# STM32H5E5 register map
File version: 1.0
CPU: CM33 r0p0, little endian, MPU, FPU, 4 interrupt priority bits
Registers are 32-bit, read-write, reset 0x0 unless marked. A register's access mark holds for its fields unless they carry their own. Offsets are from the block's base; [hi:lo] are bit positions; {n}, {i} and the like mark numbered series; 'fields as' and 'values as' point back to an identical list.

## SBS — SBS address block description
Base 0x44000400
Same registers: SBS_S 0x54000400
0x10 SBS_HDPLCR reset 0xB4 — SBS temporal isolation control register
  [7:0] INCR_HDPL — Increment HDPL value
    180=No increment; 106=Recommended value to increment HDPL level by one
0x14 SBS_HDPLSR ro reset not defined — SBS temporal isolation status register
  [7:0] HDPL — Temporal isolation level
    180=HDPL0, RSS; 81=HDPL1, iRoT; 138=HDPL2, uRoT; 111=HDPL3, application (secure)
0x18 SBS_NEXTHDPLCR — SBS next HDPL control register
  [1:0] NEXTHDPL — Index to point to a higher HDPL than the current one
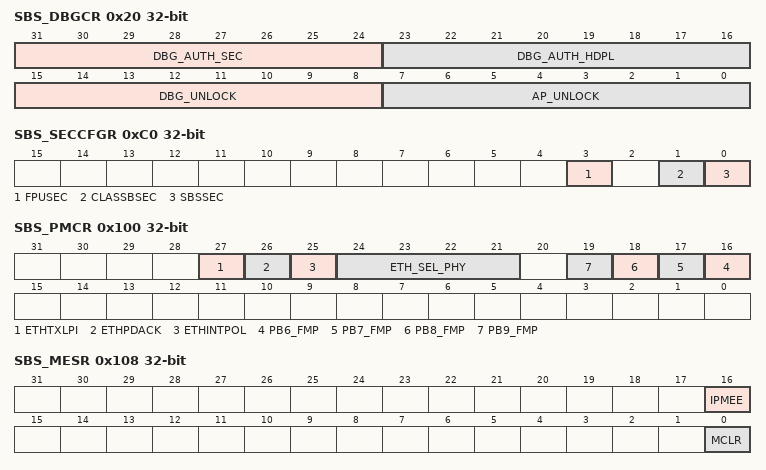
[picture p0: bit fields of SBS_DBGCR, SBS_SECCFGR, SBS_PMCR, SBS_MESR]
0x20 SBS_DBGCR — SBS debug control register
  [31:24] DBG_AUTH_SEC — Control debug opening secure/
  [23:16] DBG_AUTH_HDPL — Authenticated debug temporal isolation level
    81=HDPL1; 138=HDPL2; 111=HDPL3
  [15:8] DBG_UNLOCK — Debug unlock when DBG_AUTH_HDPL is reached
  [7:0] AP_UNLOCK — Access port unlock
0x24 SBS_DBGLOCKR reset 0xB4 — SBS debug lock register
  [7:0] DBGCFG_LOCK — Debug configuration lock
    180=Writes to SBS_DBGCR allowed (default)
0x34 SBS_RSSCMDR — SBS RSS command register
  [15:0] RSSCMD — RSS command
0xA0 SBS_EPOCHSELCR — SBS EPOCH selection control register
  [1:0] EPOCH_SEL — Select EPOCH value to be sent to the SAES
    0=NS_EPOCH () counter input selected; 1=SEC_EPOCH counter input selected
0xC0 SBS_SECCFGR — SBS security mode configuration control register
  [3] FPUSEC — FPU security enable
    0=SBS_FPUIMP register accessible through secure or transaction; 1=SBS_FPUIMP register accessible only through secure transaction
  [1] CLASSBSEC — ClassB security enable
    0=SBS_CFGR2 register accessible through secure or transaction; 1=SBS_CFGR2 register accessible only through secure transaction
  [0] SBSSEC — SBS clock control, memory-erase status register and compensation cell register security enable
    0=SBS_MESR, SBS_CCCSR, SBS_CCVALR, SBS_CCSWCR registers accessible through secure or transaction; 1=SBS_MESR, SBS_CCCSR, SBS_CCVALR, SBS_CCSWCR registers accessible only through secure transaction
0x100 SBS_PMCR — SBS product mode and configuration register
  [27] ETHTXLPI ro — ETH TxLPI status
  [26] ETHPDACK ro — ETH power-down acknowledge
    0=ETH functional / power-down sequence not yet completed; 1=ETH power-down sequence completed
  [25] ETHINTPOL — ETH external PHY interrupt polarity configuration
    0=active high; 1=active low
  [24:21] ETH_SEL_PHY — Ethernet PHY interface selection
    0=GMII or MII; 4=RMII; 8=10BT1S
  [n+10] PB{n}_FMP (n=6..9) — Fast-mode Plus driving capability activation on PB{n}
    0=PB{n} pin operates in standard mode; 1=Fm+ mode is enabled on PB{n} pin and the speed control is bypassed
0x104 SBS_FPUIMR reset 0x1F — SBS FPU interrupt mask register
  [5:0] FPU_IE — FPU interrupt enable
0x108 SBS_MESR (reset mask 0xFFFFFFF0) — SBS memory erase status register
  [16] IPMEE — ICACHE erase status
    0=ICACHE and PKA RAM erase ongoing; 1=ICACHE and PKA SRAM erase done
  [0] MCLR — device memories erase status
    0=memory erase ongoing if not yet cleared by software; 1=Memory erase done
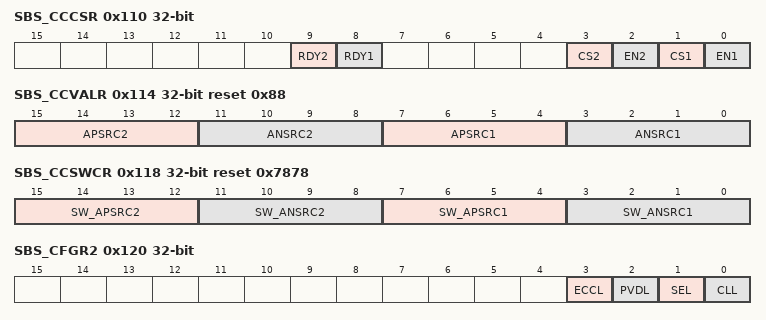
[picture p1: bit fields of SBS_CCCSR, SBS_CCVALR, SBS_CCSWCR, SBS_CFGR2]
0x110 SBS_CCCSR — SBS compensation cell for I/Os control and status register
  [9] RDY2 ro — VDDIO2 compensation cell ready flag
    0=VDDIO2 compensation cell not ready; 1=VDDIO2 compensation cell ready (code value provided by the cell can be used)
  [8] RDY1 ro — VDDIO compensation cell ready flag
    0=VDDIO compensation cell not ready; 1=VDDIO compensation cell ready (code value provided by the cell can be used)
  [3] CS2 — code selection for VDDIO2 power rail (reset value set to 1)
    0=Code from the cell (available in SBS_CCVR); 1=Code from SBS_CCCR
  [2] EN2 — enable compensation cell for VDDIO2 power rail
    0=I/O compensation cell disabled; 1=I/O compensation cell enabled
  [1] CS1 — code selection for VDDIO power rail (reset value set to 1)
    0=Code from the cell (available in the SBS_CCVR); 1=Code from SBS_CCCR
  [0] EN1 — enable compensation cell for VDDIO power rail
    values as EN2
0x114 SBS_CCVALR ro reset 0x88 — SBS compensation cell for I/Os value register
  [15:12] APSRC2 — compensation value for the PMOS transistor
  [11:8] ANSRC2 — Compensation value for the NMOS transistor
  [7:4] APSRC1 — compensation value for the PMOS transistor
  [3:0] ANSRC1 — compensation value for the NMOS transistor
0x118 SBS_CCSWCR reset 0x7878 — SBS compensation cell for I/Os software code register
  [15:12] SW_APSRC2 — PMOS compensation code for the Vless thansub>DDIOless than/sub> power rails
  [11:8] SW_ANSRC2 — NMOS compensation code for VDDIO power rails
  [7:4] SW_APSRC1 — PMOS compensation code for the VDD power rails
  [3:0] SW_ANSRC1 — NMOS compensation code for VDD power rails
0x120 SBS_CFGR2 — SBS Class B register
  [3] ECCL — ECC lock
    0=double ECC error flag disconnected to timer break inputs; 1=double ECC error flag connected to timer break inputs
  [2] PVDL — PVD lock
    0=PVD interrupt disconnected from timer break inputs; 1=PVD interrupt is connected to timer break inputs
  [1] SEL — SRAM ECC error lock
    0=SRAM double ECC error flag disconnected from timer break inputs; 1=SRAM double ECC error flag connected to timer break inputs
  [0] CLL — core lockup lock
    0=lockup output disconnected from timer break inputs; 1=lockup output connected to timer break inputs
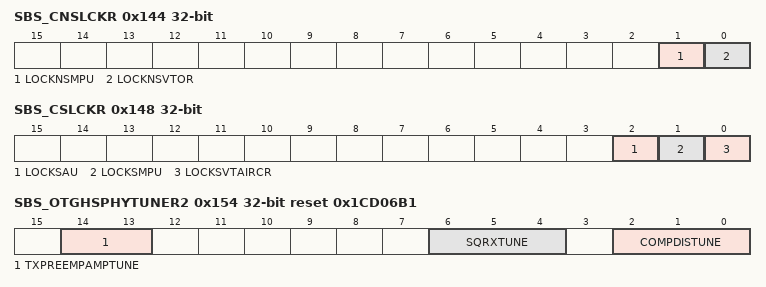
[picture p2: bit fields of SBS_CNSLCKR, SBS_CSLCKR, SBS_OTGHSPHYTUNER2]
0x144 SBS_CNSLCKR — SBS CPU lock register
  [1] LOCKNSMPU — MPU register lock
    0=MPU registers write enabled; 1=MPU registers write disabled
  [0] LOCKNSVTOR — VTOR_NS register lock
    0=VTOR_NS register write enabled; 1=VTOR_NS register write disabled
0x148 SBS_CSLCKR — SBS CPU secure lock register
  [2] LOCKSAU — SAU registers lock
    0=SAU registers write enabled; 1=SAU registers write disabled
  [1] LOCKSMPU — secure MPU registers lock
    0=Secure MPU registers writes enabled; 1=Secure MPU registers writes disabled
  [0] LOCKSVTAIRCR — VTOR_S and AIRCR register lock
    0=VTOR_S register PRIS and BFHFNMINS bits in the AIRCR register write enabled; 1=VTOR_S register PRIS and BFHFNMINS bits in the AIRCR register write disabled
0x14C SBS_ECCNMIR — SBS flift ECC NMI mask register
  [0] ECCNMI_MASK_EN — NMI behavior setup when a double ECC error occurs on flitf data part
    0=NMI generated if a double ECC error in the flitf data part; 1=NMI not generated if a double ECC error in the flitf data part
0x154 SBS_OTGHSPHYTUNER2 reset 0x1CD06B1 — SBS OTG_HS PHY tune register 2
  [14:13] TXPREEMPAMPTUNE — High-speed (HS) transmitter preemphasis current control
    3=HS transmitter preemphasis circuit sources 3x preemphasis current; 2=HS transmitter preemphasis circuit sources 2x preemphasis current; 1=HS transmitter preemphasis circuit sources 1x preemphasis current; 0=HS transmitter preemphasis circuit disabled
  [6:4] SQRXTUNE — Squelch threshold adjustment
    0=+15% (recommended value); 3=0% (default value)
  [2:0] COMPDISTUNE — Disconnect threshold adjustment
    2=+5; 1=0% (default value)
